# ESP32-S31 register map
Vendor: ESPRESSIF SYSTEMS (SHANGHAI) CO., LTD.; Series: ESP32 S-Series; File version: 1
CPU: RV32IMAFC r0p0, little endian, no MPU, FPU, 0 interrupt priority bits
Address unit: 32 bits
Registers are 32-bit, read-write, reset 0x0 unless marked. A register's access mark holds for its fields unless they carry their own. Offsets are from the block's base; [hi:lo] are bit positions; {n}, {i} and the like mark numbered series.

## SPI2 — SPI (Serial Peripheral Interface) Controller 2
Base 0x2038F000
Same registers: SPI3 0x20390000
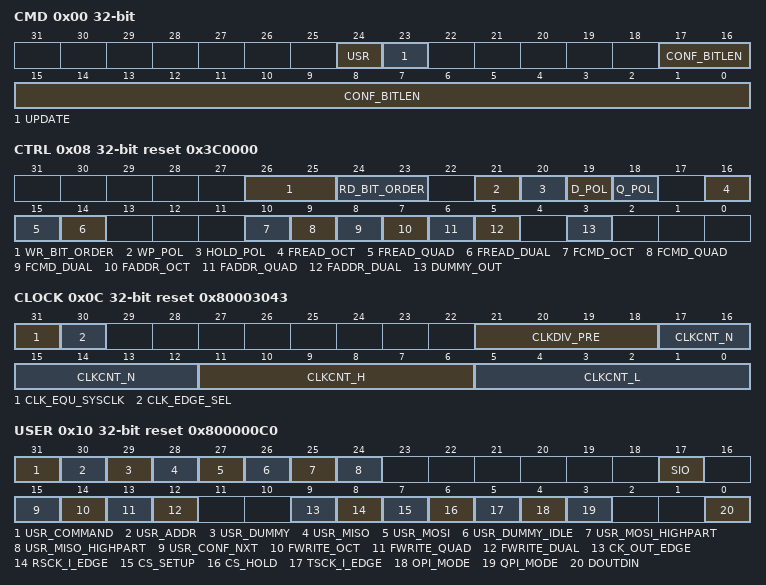
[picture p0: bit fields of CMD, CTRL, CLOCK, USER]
0x00 CMD — Command control register
  [24] USR — User define command enable. An operation will be triggered when the bit is set. The bit will be cleared once the operation done.1: enable 0: disable. Can not be changed by CONF_buf.
  [23] UPDATE — Set this bit to synchronize SPI registers from APB clock domain into SPI module clock domain, which is only used in SPI master mode.
  [17:0] CONF_BITLEN — Define the APB cycles of SPI_CONF state. Can be configured in CONF state.
0x04 ADDR — Address value register
  [31:0] USR_ADDR_VALUE — Address to slave. Can be configured in CONF state.
0x08 CTRL reset 0x3C0000 — SPI control register
  [26:25] WR_BIT_ORDER — In command address write-data (MOSI) phases 1: LSB firs 0: MSB first. Can be configured in CONF state.
  [24:23] RD_BIT_ORDER — In read-data (MISO) phase 1: LSB first 0: MSB first. Can be configured in CONF state.
  [21] WP_POL — Write protect signal output when SPI is idle. 1: output high, 0: output low. Can be configured in CONF state.
  [20] HOLD_POL — SPI_HOLD output value when SPI is idle. 1: output high, 0: output low. Can be configured in CONF state.
  [19] D_POL — The bit is used to set MOSI line polarity, 1: high 0, low. Can be configured in CONF state.
  [18] Q_POL — The bit is used to set MISO line polarity, 1: high 0, low. Can be configured in CONF state.
  [16] FREAD_OCT — In the read operations read-data phase apply 8 signals. 1: enable 0: disable. Can be configured in CONF state.
  [15] FREAD_QUAD — In the read operations read-data phase apply 4 signals. 1: enable 0: disable. Can be configured in CONF state.
  [14] FREAD_DUAL — In the read operations, read-data phase apply 2 signals. 1: enable 0: disable. Can be configured in CONF state.
  [10] FCMD_OCT — Apply 8 signals during command phase 1:enable 0: disable. Can be configured in CONF state.
  [9] FCMD_QUAD — Apply 4 signals during command phase 1:enable 0: disable. Can be configured in CONF state.
  [8] FCMD_DUAL — Apply 2 signals during command phase 1:enable 0: disable. Can be configured in CONF state.
  [7] FADDR_OCT — Apply 8 signals during addr phase 1:enable 0: disable. Can be configured in CONF state.
  [6] FADDR_QUAD — Apply 4 signals during addr phase 1:enable 0: disable. Can be configured in CONF state.
  [5] FADDR_DUAL — Apply 2 signals during addr phase 1:enable 0: disable. Can be configured in CONF state.
  [3] DUMMY_OUT — 0: In the dummy phase, the FSPI bus signals are not output. 1: In the dummy phase, the FSPI bus signals are output. Can be configured in CONF state.
0x0C CLOCK reset 0x80003043 — SPI clock control register
  [31] CLK_EQU_SYSCLK — In the master mode 1: spi_clk is eqaul to system 0: spi_clk is divided from system clock. Can be configured in CONF state.
  [30] CLK_EDGE_SEL — Configures use standard clock sampling edge or delay the sampling edge by half a cycle in master transfer.\\ 0: clock sampling edge is delayed by half a cycle.\\ 1: clock sampling edge is standard.\\ Can be configured in CONF state.
  [21:18] CLKDIV_PRE — In the master mode it is pre-divider of spi_clk. Can be configured in CONF state.
  [17:12] CLKCNT_N — In the master mode it is the divider of spi_clk. So spi_clk frequency is system/(spi_clkdiv_pre+1)/(spi_clkcnt_N+1). Can be configured in CONF state.
  [11:6] CLKCNT_H — In the master mode it must be floor((spi_clkcnt_N+1)/2-1). In the slave mode it must be 0. Can be configured in CONF state.
  [5:0] CLKCNT_L — In the master mode it must be equal to spi_clkcnt_N. In the slave mode it must be 0. Can be configured in CONF state.
0x10 USER reset 0x800000C0 — SPI USER control register
  [31] USR_COMMAND — This bit enable the command phase of an operation. Can be configured in CONF state.
  [30] USR_ADDR — This bit enable the address phase of an operation. Can be configured in CONF state.
  [29] USR_DUMMY — This bit enable the dummy phase of an operation. Can be configured in CONF state.
  [28] USR_MISO — This bit enable the read-data phase of an operation. Can be configured in CONF state.
  [27] USR_MOSI — This bit enable the write-data phase of an operation. Can be configured in CONF state.
  [26] USR_DUMMY_IDLE — spi clock is disable in dummy phase when the bit is enable. Can be configured in CONF state.
  [25] USR_MOSI_HIGHPART — write-data phase only access to high-part of the buffer spi_w8~spi_w15. 1: enable 0: disable. Can be configured in CONF state.
  [24] USR_MISO_HIGHPART — read-data phase only access to high-part of the buffer spi_w8~spi_w15. 1: enable 0: disable. Can be configured in CONF state.
  [17] SIO — Set the bit to enable 3-line half duplex communication mosi and miso signals share the same pin. 1: enable 0: disable. Can be configured in CONF state.
  [15] USR_CONF_NXT — 1: Enable the DMA CONF phase of next seg-trans operation, which means seg-trans will continue. 0: The seg-trans will end after the current SPI seg-trans or this is not seg-trans mode. Can be configured in CONF state.
  [14] FWRITE_OCT — In the write operations read-data phase apply 8 signals. Can be configured in CONF state.
  [13] FWRITE_QUAD — In the write operations read-data phase apply 4 signals. Can be configured in CONF state.
  [12] FWRITE_DUAL — In the write operations read-data phase apply 2 signals. Can be configured in CONF state.
  [9] CK_OUT_EDGE — the bit combined with spi_mosi_delay_mode bits to set mosi signal delay mode. Can be configured in CONF state.
  [8] RSCK_I_EDGE — In the slave mode, this bit can be used to change the polarity of rsck. 0: rsck = !spi_ck_i. 1:rsck = spi_ck_i.
  [7] CS_SETUP — spi cs is enable when spi is in prepare phase. 1: enable 0: disable. Can be configured in CONF state.
  [6] CS_HOLD — spi cs keep low when spi is in done phase. 1: enable 0: disable. Can be configured in CONF state.
  [5] TSCK_I_EDGE — In the slave mode, this bit can be used to change the polarity of tsck. 0: tsck = spi_ck_i. 1:tsck = !spi_ck_i.
  [4] OPI_MODE — Just for master mode. 1: spi controller is in OPI mode (all in 8-b-m). 0: others. Can be configured in CONF state.
  [3] QPI_MODE — Both for master mode and slave mode. 1: spi controller is in QPI mode. 0: others. Can be configured in CONF state.
  [0] DOUTDIN — Set the bit to enable full duplex communication. 1: enable 0: disable. Can be configured in CONF state.
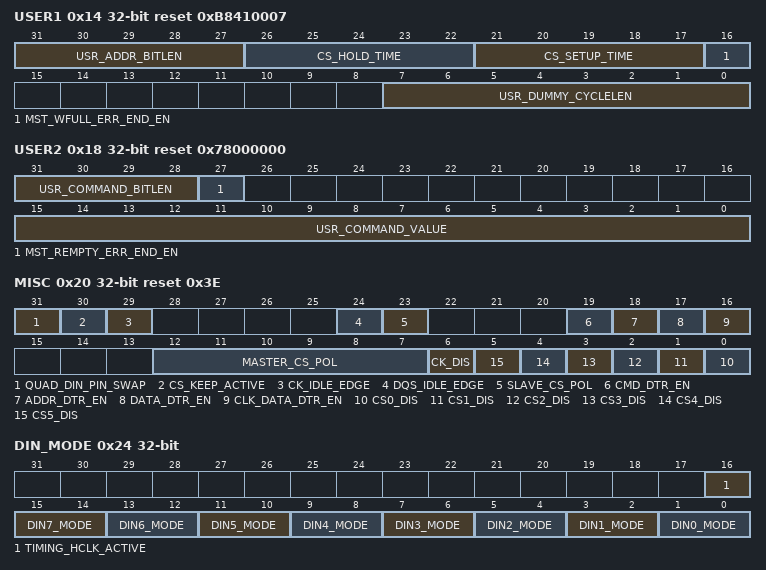
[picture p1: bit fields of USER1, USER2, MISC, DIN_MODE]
0x14 USER1 reset 0xB8410007 — SPI USER control register 1
  [31:27] USR_ADDR_BITLEN — The length in bits of address phase. The register value shall be (bit_num-1). Can be configured in CONF state.
  [26:22] CS_HOLD_TIME — delay cycles of cs pin by spi clock this bits are combined with spi_cs_hold bit. Can be configured in CONF state.
  [21:17] CS_SETUP_TIME — (cycles+1) of prepare phase by spi clock this bits are combined with spi_cs_setup bit. Can be configured in CONF state.
  [16] MST_WFULL_ERR_END_EN — 1: SPI transfer is ended when SPI RX AFIFO wfull error is valid in GP-SPI master FD/HD-mode. 0: SPI transfer is not ended when SPI RX AFIFO wfull error is valid in GP-SPI master FD/HD-mode.
  [7:0] USR_DUMMY_CYCLELEN — The length in spi_clk cycles of dummy phase. The register value shall be (cycle_num-1). Can be configured in CONF state.
0x18 USER2 reset 0x78000000 — SPI USER control register 2
  [31:28] USR_COMMAND_BITLEN — The length in bits of command phase. The register value shall be (bit_num-1). Can be configured in CONF state.
  [27] MST_REMPTY_ERR_END_EN — 1: SPI transfer is ended when SPI TX AFIFO read empty error is valid in GP-SPI master FD/HD-mode. 0: SPI transfer is not ended when SPI TX AFIFO read empty error is valid in GP-SPI master FD/HD-mode.
  [15:0] USR_COMMAND_VALUE — The value of command. Can be configured in CONF state.
0x1C MS_DLEN — SPI data bit length control register
  [17:0] MS_DATA_BITLEN — The value of these bits is the configured SPI transmission data bit length in master mode DMA controlled transfer or CPU controlled transfer. The value is also the configured bit length in slave mode DMA RX controlled transfer. The register value shall be (bit_num-1). Can be configured in CONF state.
0x20 MISC reset 0x3E — SPI misc register
  [31] QUAD_DIN_PIN_SWAP — 1: SPI quad input swap enable, swap FSPID with FSPIQ, swap FSPIWP with FSPIHD. 0: spi quad input swap disable. Can be configured in CONF state.
  [30] CS_KEEP_ACTIVE — spi cs line keep low when the bit is set. Can be configured in CONF state.
  [29] CK_IDLE_EDGE — 1: spi clk line is high when idle 0: spi clk line is low when idle. Can be configured in CONF state.
  [24] DQS_IDLE_EDGE — The default value of spi_dqs. Can be configured in CONF state.
  [23] SLAVE_CS_POL — spi slave input cs polarity select. 1: inv 0: not change. Can be configured in CONF state.
  [19] CMD_DTR_EN — 1: SPI clk and data of SPI_SEND_CMD state are in DTR mode, including master 1/2/4/8-bm. 0: SPI clk and data of SPI_SEND_CMD state are in STR mode. Can be configured in CONF state.
  [18] ADDR_DTR_EN — 1: SPI clk and data of SPI_SEND_ADDR state are in DTR mode, including master 1/2/4/8-bm. 0: SPI clk and data of SPI_SEND_ADDR state are in STR mode. Can be configured in CONF state.
  [17] DATA_DTR_EN — 1: SPI clk and data of SPI_DOUT and SPI_DIN state are in DTR mode, including master 1/2/4/8-bm. 0: SPI clk and data of SPI_DOUT and SPI_DIN state are in STR mode. Can be configured in CONF state.
  [16] CLK_DATA_DTR_EN — 1: SPI master DTR mode is applied to SPI clk, data and spi_dqs. 0: SPI master DTR mode is only applied to spi_dqs. This bit should be used with bit 17/18/19.
  [12:7] MASTER_CS_POL — In the master mode the bits are the polarity of spi cs line, the value is equivalent to spi_cs ^ spi_master_cs_pol. Can be configured in CONF state.
  [6] CK_DIS — 1: spi clk out disable, 0: spi clk out enable. Can be configured in CONF state.
  [n] CS{n}_DIS (n=0..5) — SPI CS{n} pin enable, 1: disable CS{n}, 0: spi_cs{n} signal is from/to CS{n} pin. Can be configured in CONF state.
0x24 DIN_MODE — SPI input delay mode configuration
  [16] TIMING_HCLK_ACTIVE — 1:enable hclk in SPI input timing module. 0: disable it. Can be configured in CONF state.
  [2n+1:2n] DIN{n}_MODE (n=0..7) — the input signals are delayed by SPI module clock cycles, 0: input without delayed, 1: input with the posedge of clk_apb,2 input with the negedge of clk_apb, 3: input with the spi_clk. Can be configured in CONF state.
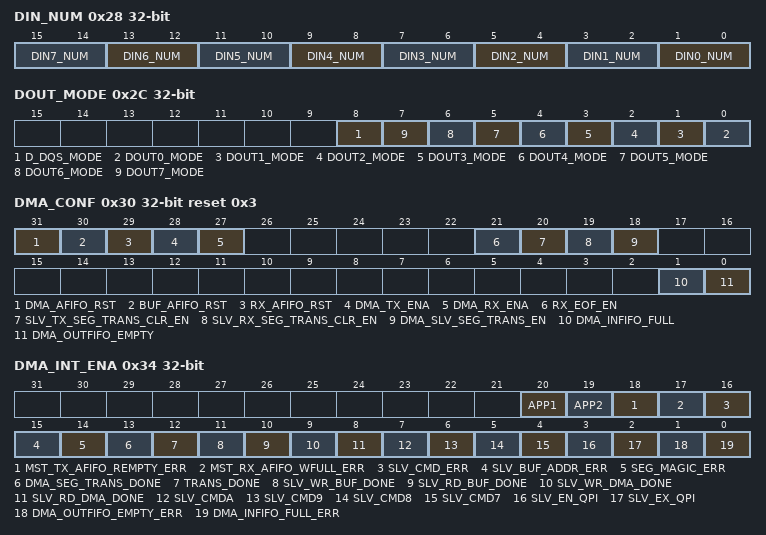
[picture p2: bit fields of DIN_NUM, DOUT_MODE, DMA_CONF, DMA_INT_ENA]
0x28 DIN_NUM — SPI input delay number configuration
  [2n+1:2n] DIN{n}_NUM (n=0..7) — the input signals are delayed by SPI module clock cycles, 0: delayed by 1 cycle, 1: delayed by 2 cycles,... Can be configured in CONF state.
0x2C DOUT_MODE — SPI output delay mode configuration
  [8] D_DQS_MODE — The output signal SPI_DQS is delayed by the SPI module clock, 0: output without delayed, 1: output delay for a SPI module clock cycle at its negative edge. Can be configured in CONF state.
  [n] DOUT{n}_MODE (n=0..7) — The output signal {n} is delayed by the SPI module clock, 0: output without delayed, 1: output delay for a SPI module clock cycle at its negative edge. Can be configured in CONF state.
0x30 DMA_CONF access per field reset 0x3 — SPI DMA control register
  [31] DMA_AFIFO_RST wo — Set this bit to reset DMA TX AFIFO, which is used to send data out in SPI slave DMA controlled mode transfer.
  [30] BUF_AFIFO_RST wo — Set this bit to reset BUF TX AFIFO, which is used send data out in SPI slave CPU controlled mode transfer and master mode transfer.
  [29] RX_AFIFO_RST wo — Set this bit to reset RX AFIFO, which is used to receive data in SPI master and slave mode transfer.
  [28] DMA_TX_ENA rw — Set this bit to enable SPI DMA controlled send data mode.
  [27] DMA_RX_ENA rw — Set this bit to enable SPI DMA controlled receive data mode.
  [21] RX_EOF_EN rw — 1: spi_dma_inlink_eof is set when the number of dma pushed data bytes is equal to the value of spi_slv/mst_dma_rd_bytelen[19:0] in spi dma transition. 0: spi_dma_inlink_eof is set by spi_trans_done in non-seg-trans or spi_dma_seg_trans_done in seg-trans.
  [20] SLV_TX_SEG_TRANS_CLR_EN rw — 1: spi_dma_outfifo_empty_vld is cleared by spi slave cmd 6. 0: spi_dma_outfifo_empty_vld is cleared by spi_trans_done.
  [19] SLV_RX_SEG_TRANS_CLR_EN rw — 1: spi_dma_infifo_full_vld is cleared by spi slave cmd 5. 0: spi_dma_infifo_full_vld is cleared by spi_trans_done.
  [18] DMA_SLV_SEG_TRANS_EN rw — Enable dma segment transfer in spi dma half slave mode. 1: enable. 0: disable.
  [1] DMA_INFIFO_FULL ro — Records the status of DMA RX FIFO. 1: DMA RX FIFO is not ready for receiving data. 0: DMA RX FIFO is ready for receiving data.
  [0] DMA_OUTFIFO_EMPTY ro — Records the status of DMA TX FIFO. 1: DMA TX FIFO is not ready for sending data. 0: DMA TX FIFO is ready for sending data.
0x34 DMA_INT_ENA — SPI interrupt enable register
  [20] APP1 — The enable bit for SPI_APP1_INT interrupt.
  [19] APP2 — The enable bit for SPI_APP2_INT interrupt.
  [18] MST_TX_AFIFO_REMPTY_ERR — The enable bit for SPI_MST_TX_AFIFO_REMPTY_ERR_INT interrupt.
  [17] MST_RX_AFIFO_WFULL_ERR — The enable bit for SPI_MST_RX_AFIFO_WFULL_ERR_INT interrupt.
  [16] SLV_CMD_ERR — The enable bit for SPI_SLV_CMD_ERR_INT interrupt.
  [15] SLV_BUF_ADDR_ERR — The enable bit for SPI_SLV_BUF_ADDR_ERR_INT interrupt.
  [14] SEG_MAGIC_ERR — The enable bit for SPI_SEG_MAGIC_ERR_INT interrupt.
  [13] DMA_SEG_TRANS_DONE — The enable bit for SPI_DMA_SEG_TRANS_DONE_INT interrupt.
  [12] TRANS_DONE — The enable bit for SPI_TRANS_DONE_INT interrupt.
  [11] SLV_WR_BUF_DONE — The enable bit for SPI_SLV_WR_BUF_DONE_INT interrupt.
  [10] SLV_RD_BUF_DONE — The enable bit for SPI_SLV_RD_BUF_DONE_INT interrupt.
  [9] SLV_WR_DMA_DONE — The enable bit for SPI_SLV_WR_DMA_DONE_INT interrupt.
  [8] SLV_RD_DMA_DONE — The enable bit for SPI_SLV_RD_DMA_DONE_INT interrupt.
  [7] SLV_CMDA — The enable bit for SPI slave CMDA interrupt.
  [6] SLV_CMD9 — The enable bit for SPI slave CMD9 interrupt.
  [5] SLV_CMD8 — The enable bit for SPI slave CMD8 interrupt.
  [4] SLV_CMD7 — The enable bit for SPI slave CMD7 interrupt.
  [3] SLV_EN_QPI — The enable bit for SPI slave En_QPI interrupt.
  [2] SLV_EX_QPI — The enable bit for SPI slave Ex_QPI interrupt.
  [1] DMA_OUTFIFO_EMPTY_ERR — The enable bit for SPI_DMA_OUTFIFO_EMPTY_ERR_INT interrupt.
  [0] DMA_INFIFO_FULL_ERR — The enable bit for SPI_DMA_INFIFO_FULL_ERR_INT interrupt.
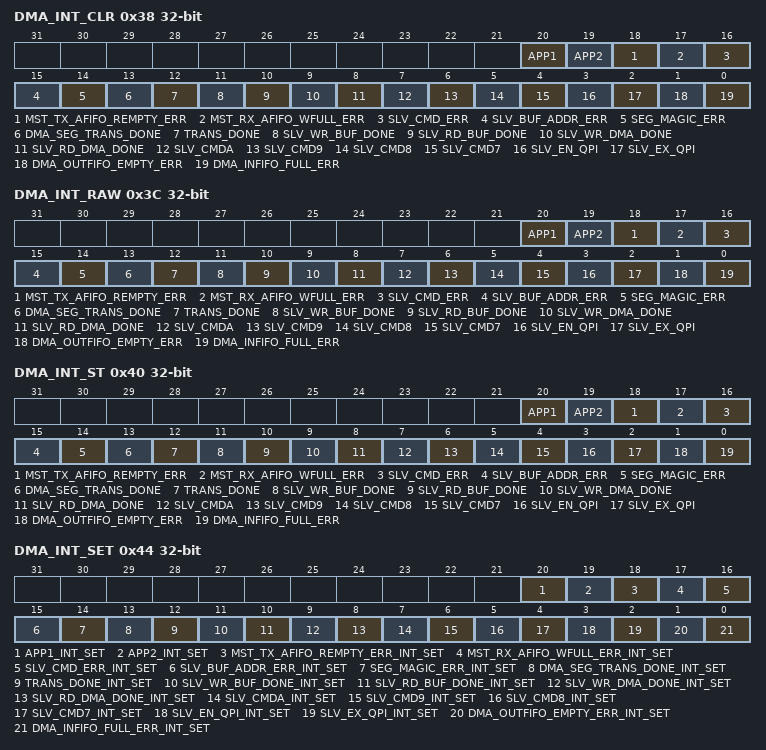
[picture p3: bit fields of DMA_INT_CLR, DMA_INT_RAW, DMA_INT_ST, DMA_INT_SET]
0x38 DMA_INT_CLR wo — SPI interrupt clear register
  [20] APP1 write-1-clears — The clear bit for SPI_APP1_INT interrupt.
  [19] APP2 write-1-clears — The clear bit for SPI_APP2_INT interrupt.
  [18] MST_TX_AFIFO_REMPTY_ERR write-1-clears — The clear bit for SPI_MST_TX_AFIFO_REMPTY_ERR_INT interrupt.
  [17] MST_RX_AFIFO_WFULL_ERR write-1-clears — The clear bit for SPI_MST_RX_AFIFO_WFULL_ERR_INT interrupt.
  [16] SLV_CMD_ERR write-1-clears — The clear bit for SPI_SLV_CMD_ERR_INT interrupt.
  [15] SLV_BUF_ADDR_ERR write-1-clears — The clear bit for SPI_SLV_BUF_ADDR_ERR_INT interrupt.
  [14] SEG_MAGIC_ERR write-1-clears — The clear bit for SPI_SEG_MAGIC_ERR_INT interrupt.
  [13] DMA_SEG_TRANS_DONE write-1-clears — The clear bit for SPI_DMA_SEG_TRANS_DONE_INT interrupt.
  [12] TRANS_DONE write-1-clears — The clear bit for SPI_TRANS_DONE_INT interrupt.
  [11] SLV_WR_BUF_DONE write-1-clears — The clear bit for SPI_SLV_WR_BUF_DONE_INT interrupt.
  [10] SLV_RD_BUF_DONE write-1-clears — The clear bit for SPI_SLV_RD_BUF_DONE_INT interrupt.
  [9] SLV_WR_DMA_DONE write-1-clears — The clear bit for SPI_SLV_WR_DMA_DONE_INT interrupt.
  [8] SLV_RD_DMA_DONE write-1-clears — The clear bit for SPI_SLV_RD_DMA_DONE_INT interrupt.
  [7] SLV_CMDA write-1-clears — The clear bit for SPI slave CMDA interrupt.
  [6] SLV_CMD9 write-1-clears — The clear bit for SPI slave CMD9 interrupt.
  [5] SLV_CMD8 write-1-clears — The clear bit for SPI slave CMD8 interrupt.
  [4] SLV_CMD7 write-1-clears — The clear bit for SPI slave CMD7 interrupt.
  [3] SLV_EN_QPI write-1-clears — The clear bit for SPI slave En_QPI interrupt.
  [2] SLV_EX_QPI write-1-clears — The clear bit for SPI slave Ex_QPI interrupt.
  [1] DMA_OUTFIFO_EMPTY_ERR write-1-clears — The clear bit for SPI_DMA_OUTFIFO_EMPTY_ERR_INT interrupt.
  [0] DMA_INFIFO_FULL_ERR write-1-clears — The clear bit for SPI_DMA_INFIFO_FULL_ERR_INT interrupt.
0x3C DMA_INT_RAW — SPI interrupt raw register
  [20] APP1 — The raw bit for SPI_APP1_INT interrupt. The value is only controlled by software.
  [19] APP2 — The raw bit for SPI_APP2_INT interrupt. The value is only controlled by software.
  [18] MST_TX_AFIFO_REMPTY_ERR — The raw bit for SPI_MST_TX_AFIFO_REMPTY_ERR_INT interrupt. 1: There is a TX BUF AFIFO read-empty error when SPI outputs data in master mode. 0: Others.
  [17] MST_RX_AFIFO_WFULL_ERR — The raw bit for SPI_MST_RX_AFIFO_WFULL_ERR_INT interrupt. 1: There is a RX AFIFO write-full error when SPI inputs data in master mode. 0: Others.
  [16] SLV_CMD_ERR — The raw bit for SPI_SLV_CMD_ERR_INT interrupt. 1: The slave command value in the current SPI slave HD mode transmission is not supported. 0: Others.
  [15] SLV_BUF_ADDR_ERR — The raw bit for SPI_SLV_BUF_ADDR_ERR_INT interrupt. 1: The accessing data address of the current SPI slave mode CPU controlled FD, Wr_BUF or Rd_BUF transmission is bigger than 63. 0: Others.
  [14] SEG_MAGIC_ERR — The raw bit for SPI_SEG_MAGIC_ERR_INT interrupt. 1: The magic value in CONF buffer is error in the DMA seg-conf-trans. 0: others.
  [13] DMA_SEG_TRANS_DONE — The raw bit for SPI_DMA_SEG_TRANS_DONE_INT interrupt. 1: spi master DMA full-duplex/half-duplex seg-conf-trans ends or slave half-duplex seg-trans ends. And data has been pushed to corresponding memory. 0: seg-conf-trans or seg-trans is not ended or not occurred.
  [12] TRANS_DONE — The raw bit for SPI_TRANS_DONE_INT interrupt. 1: SPI master mode transmission is ended. 0: others.
  [11] SLV_WR_BUF_DONE — The raw bit for SPI_SLV_WR_BUF_DONE_INT interrupt. 1: SPI slave mode Wr_BUF transmission is ended. 0: Others.
  [10] SLV_RD_BUF_DONE — The raw bit for SPI_SLV_RD_BUF_DONE_INT interrupt. 1: SPI slave mode Rd_BUF transmission is ended. 0: Others.
  [9] SLV_WR_DMA_DONE — The raw bit for SPI_SLV_WR_DMA_DONE_INT interrupt. 1: SPI slave mode Wr_DMA transmission is ended. 0: Others.
  [8] SLV_RD_DMA_DONE — The raw bit for SPI_SLV_RD_DMA_DONE_INT interrupt. 1: SPI slave mode Rd_DMA transmission is ended. 0: Others.
  [7] SLV_CMDA — The raw bit for SPI slave CMDA interrupt. 1: SPI slave mode CMDA transmission is ended. 0: Others.
  [6] SLV_CMD9 — The raw bit for SPI slave CMD9 interrupt. 1: SPI slave mode CMD9 transmission is ended. 0: Others.
  [5] SLV_CMD8 — The raw bit for SPI slave CMD8 interrupt. 1: SPI slave mode CMD8 transmission is ended. 0: Others.
  [4] SLV_CMD7 — The raw bit for SPI slave CMD7 interrupt. 1: SPI slave mode CMD7 transmission is ended. 0: Others.
  [3] SLV_EN_QPI — The raw bit for SPI slave En_QPI interrupt. 1: SPI slave mode En_QPI transmission is ended. 0: Others.
  [2] SLV_EX_QPI — The raw bit for SPI slave Ex_QPI interrupt. 1: SPI slave mode Ex_QPI transmission is ended. 0: Others.
  [1] DMA_OUTFIFO_EMPTY_ERR — 1: The current data rate of DMA TX is smaller than that of SPI. SPI will stop in master mode and send out all 0 in slave mode. 0: Others.
  [0] DMA_INFIFO_FULL_ERR — 1: The current data rate of DMA Rx is smaller than that of SPI, which will lose the receive data. 0: Others.
0x40 DMA_INT_ST ro — SPI interrupt status register
  [20] APP1 — The status bit for SPI_APP1_INT interrupt.
  [19] APP2 — The status bit for SPI_APP2_INT interrupt.
  [18] MST_TX_AFIFO_REMPTY_ERR — The status bit for SPI_MST_TX_AFIFO_REMPTY_ERR_INT interrupt.
  [17] MST_RX_AFIFO_WFULL_ERR — The status bit for SPI_MST_RX_AFIFO_WFULL_ERR_INT interrupt.
  [16] SLV_CMD_ERR — The status bit for SPI_SLV_CMD_ERR_INT interrupt.
  [15] SLV_BUF_ADDR_ERR — The status bit for SPI_SLV_BUF_ADDR_ERR_INT interrupt.
  [14] SEG_MAGIC_ERR — The status bit for SPI_SEG_MAGIC_ERR_INT interrupt.
  [13] DMA_SEG_TRANS_DONE — The status bit for SPI_DMA_SEG_TRANS_DONE_INT interrupt.
  [12] TRANS_DONE — The status bit for SPI_TRANS_DONE_INT interrupt.
  [11] SLV_WR_BUF_DONE — The status bit for SPI_SLV_WR_BUF_DONE_INT interrupt.
  [10] SLV_RD_BUF_DONE — The status bit for SPI_SLV_RD_BUF_DONE_INT interrupt.
  [9] SLV_WR_DMA_DONE — The status bit for SPI_SLV_WR_DMA_DONE_INT interrupt.
  [8] SLV_RD_DMA_DONE — The status bit for SPI_SLV_RD_DMA_DONE_INT interrupt.
  [7] SLV_CMDA — The status bit for SPI slave CMDA interrupt.
  [6] SLV_CMD9 — The status bit for SPI slave CMD9 interrupt.
  [5] SLV_CMD8 — The status bit for SPI slave CMD8 interrupt.
  [4] SLV_CMD7 — The status bit for SPI slave CMD7 interrupt.
  [3] SLV_EN_QPI — The status bit for SPI slave En_QPI interrupt.
  [2] SLV_EX_QPI — The status bit for SPI slave Ex_QPI interrupt.
  [1] DMA_OUTFIFO_EMPTY_ERR — The status bit for SPI_DMA_OUTFIFO_EMPTY_ERR_INT interrupt.
  [0] DMA_INFIFO_FULL_ERR — The status bit for SPI_DMA_INFIFO_FULL_ERR_INT interrupt.
0x44 DMA_INT_SET wo — SPI interrupt software set register
  [20] APP1_INT_SET — The software set bit for SPI_APP1_INT interrupt.
  [19] APP2_INT_SET — The software set bit for SPI_APP2_INT interrupt.
  [18] MST_TX_AFIFO_REMPTY_ERR_INT_SET — The software set bit for SPI_MST_TX_AFIFO_REMPTY_ERR_INT interrupt.
  [17] MST_RX_AFIFO_WFULL_ERR_INT_SET — The software set bit for SPI_MST_RX_AFIFO_WFULL_ERR_INT interrupt.
  [16] SLV_CMD_ERR_INT_SET — The software set bit for SPI_SLV_CMD_ERR_INT interrupt.
  [15] SLV_BUF_ADDR_ERR_INT_SET — The software set bit for SPI_SLV_BUF_ADDR_ERR_INT interrupt.
  [14] SEG_MAGIC_ERR_INT_SET — The software set bit for SPI_SEG_MAGIC_ERR_INT interrupt.
  [13] DMA_SEG_TRANS_DONE_INT_SET — The software set bit for SPI_DMA_SEG_TRANS_DONE_INT interrupt.
  [12] TRANS_DONE_INT_SET — The software set bit for SPI_TRANS_DONE_INT interrupt.
  [11] SLV_WR_BUF_DONE_INT_SET — The software set bit for SPI_SLV_WR_BUF_DONE_INT interrupt.
  [10] SLV_RD_BUF_DONE_INT_SET — The software set bit for SPI_SLV_RD_BUF_DONE_INT interrupt.
  [9] SLV_WR_DMA_DONE_INT_SET — The software set bit for SPI_SLV_WR_DMA_DONE_INT interrupt.
  [8] SLV_RD_DMA_DONE_INT_SET — The software set bit for SPI_SLV_RD_DMA_DONE_INT interrupt.
  [7] SLV_CMDA_INT_SET — The software set bit for SPI slave CMDA interrupt.
  [6] SLV_CMD9_INT_SET — The software set bit for SPI slave CMD9 interrupt.
  [5] SLV_CMD8_INT_SET — The software set bit for SPI slave CMD8 interrupt.
  [4] SLV_CMD7_INT_SET — The software set bit for SPI slave CMD7 interrupt.
  [3] SLV_EN_QPI_INT_SET — The software set bit for SPI slave En_QPI interrupt.
  [2] SLV_EX_QPI_INT_SET — The software set bit for SPI slave Ex_QPI interrupt.
  [1] DMA_OUTFIFO_EMPTY_ERR_INT_SET — The software set bit for SPI_DMA_OUTFIFO_EMPTY_ERR_INT interrupt.
  [0] DMA_INFIFO_FULL_ERR_INT_SET — The software set bit for SPI_DMA_INFIFO_FULL_ERR_INT interrupt.
{0x98+4i} W{i} (i=0..15) — SPI CPU-controlled buffer{i}
  [31:0] BUF — data buffer
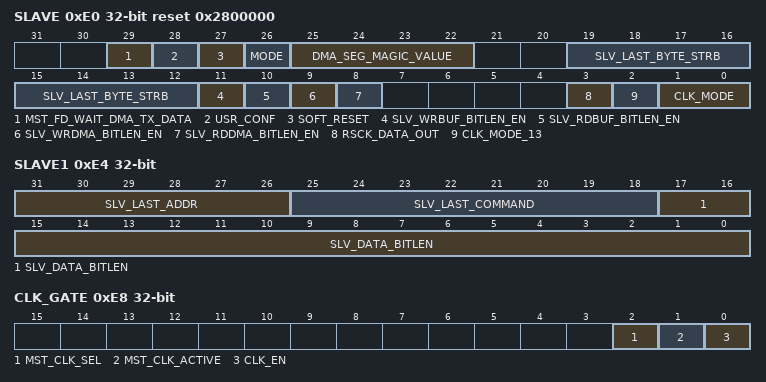
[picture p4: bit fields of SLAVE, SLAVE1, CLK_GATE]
0xE0 SLAVE access per field reset 0x2800000 — SPI slave control register
  [29] MST_FD_WAIT_DMA_TX_DATA rw — In master full-duplex mode, 1: GP-SPI will wait DMA TX data is ready before starting SPI transfer. 0: GP-SPI does not wait DMA TX data before starting SPI transfer.
  [28] USR_CONF rw — 1: Enable the DMA CONF phase of current seg-trans operation, which means seg-trans will start. 0: This is not seg-trans mode.
  [27] SOFT_RESET wo — Software reset enable, reset the spi clock line cs line and data lines. Can be configured in CONF state.
  [26] MODE rw — Set SPI work mode. 1: slave mode 0: master mode.
  [25:22] DMA_SEG_MAGIC_VALUE rw — The magic value of BM table in master DMA seg-trans.
  [19:12] SLV_LAST_BYTE_STRB ro — Represents the effective bit of the last received data byte in SPI slave FD and HD mode.
  [11] SLV_WRBUF_BITLEN_EN rw — 1: SPI_SLV_DATA_BITLEN stores data bit length of master-write-to-slave data length in CPU controlled mode(Wr_BUF). 0: others
  [10] SLV_RDBUF_BITLEN_EN rw — 1: SPI_SLV_DATA_BITLEN stores data bit length of master-read-slave data length in CPU controlled mode(Rd_BUF). 0: others
  [9] SLV_WRDMA_BITLEN_EN rw — 1: SPI_SLV_DATA_BITLEN stores data bit length of master-write-to-slave data length in DMA controlled mode(Wr_DMA). 0: others
  [8] SLV_RDDMA_BITLEN_EN rw — 1: SPI_SLV_DATA_BITLEN stores data bit length of master-read-slave data length in DMA controlled mode(Rd_DMA). 0: others
  [3] RSCK_DATA_OUT rw — It saves half a cycle when tsck is the same as rsck. 1: output data at rsck posedge 0: output data at tsck posedge
  [2] CLK_MODE_13 rw — {CPOL, CPHA},1: support spi clk mode 1 and 3, first edge output data B[0]/B[7]. 0: support spi clk mode 0 and 2, first edge output data B[1]/B[6].
  [1:0] CLK_MODE rw — SPI clock mode bits. 0: SPI clock is off when CS inactive 1: SPI clock is delayed one cycle after CS inactive 2: SPI clock is delayed two cycles after CS inactive 3: SPI clock is alwasy on. Can be configured in CONF state.
0xE4 SLAVE1 — SPI slave control register 1
  [31:26] SLV_LAST_ADDR — In the slave mode it is the value of address.
  [25:18] SLV_LAST_COMMAND — In the slave mode it is the value of command.
  [17:0] SLV_DATA_BITLEN — The transferred data bit length in SPI slave FD and HD mode.
0xE8 CLK_GATE — SPI module clock and register clock control
  [2] MST_CLK_SEL — This bit is used to select SPI module clock source in master mode. 1: PLL_CLK_80M. 0: XTAL CLK.
  [1] MST_CLK_ACTIVE — Set this bit to power on the SPI module clock.
  [0] CLK_EN — Set this bit to enable clk gate
0xF0 DATE reset 0x2403190 — Version control
  [27:0] DATE — SPI register version.
